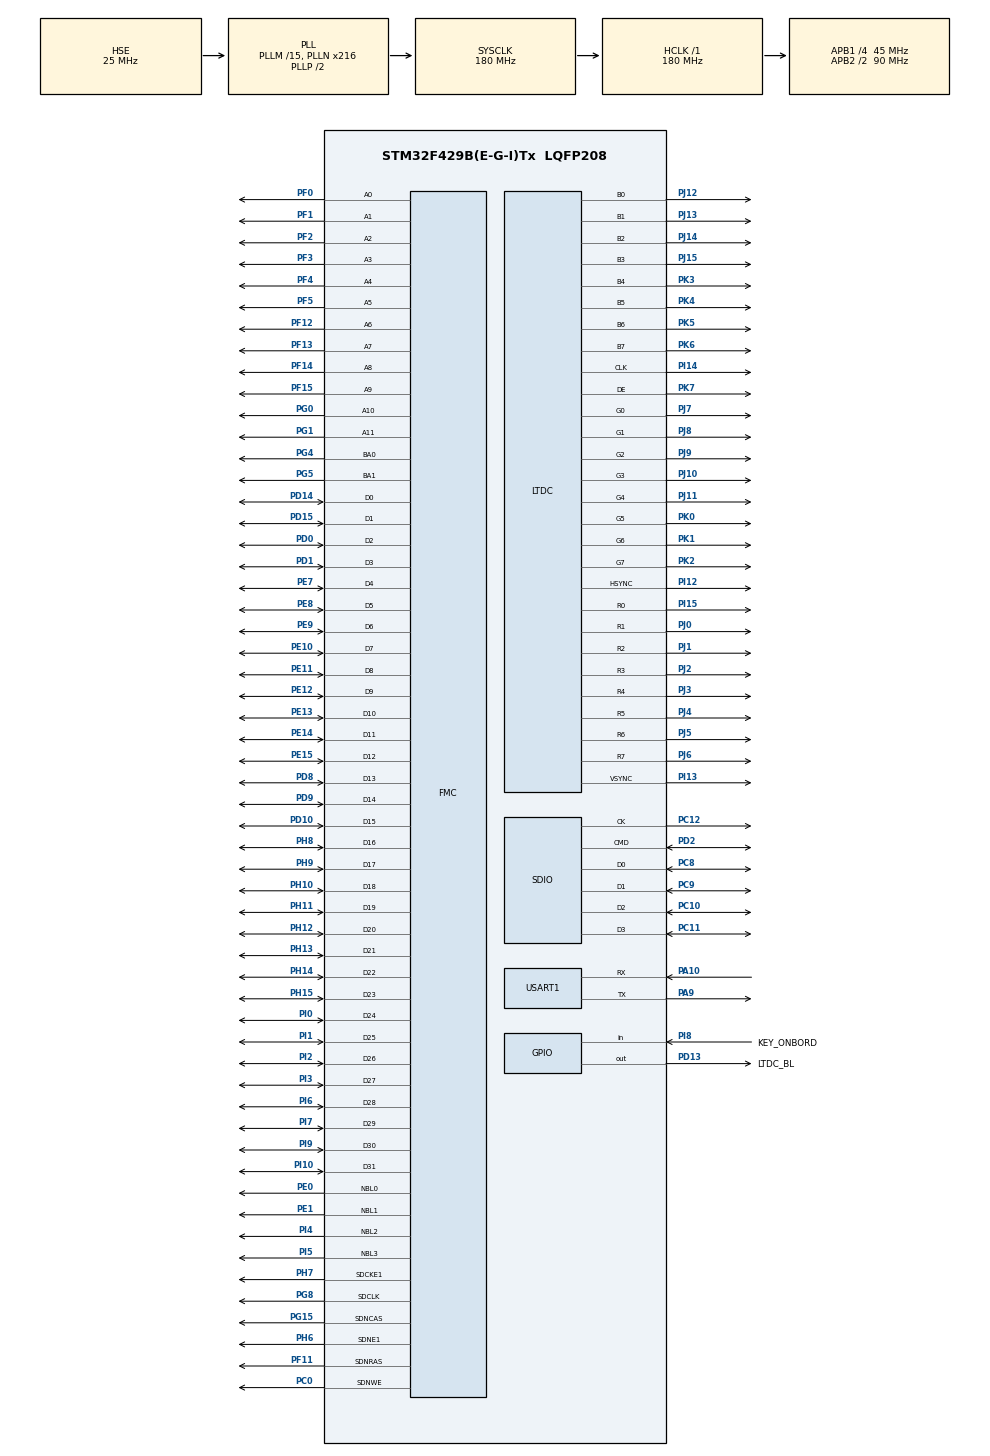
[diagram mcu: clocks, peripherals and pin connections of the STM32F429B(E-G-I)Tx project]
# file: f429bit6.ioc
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DMA2D.AlphaModeForeground=DMA2D_NO_MODIF_ALPHA
DMA2D.ColorMode=DMA2D_OUTPUT_ARGB8888
FMC.CASLatency2=FMC_SDRAM_CAS_LATENCY_3
FMC.ExitSelfRefreshDelay2=7
FMC.LoadToActiveDelay2=2
FMC.RCDDelay2=2
FMC.RPDelay2=2
FMC.ReadBurst2=FMC_SDRAM_RBURST_ENABLE
FMC.ReadPipeDelay2=FMC_SDRAM_RPIPE_DELAY_1
FMC.RowCycleDelay2=7
FMC.SDClockPeriod2=FMC_SDRAM_CLOCK_PERIOD_2
FMC.SelfRefreshTime2=4
FMC.WriteRecoveryTime2=3
LIBJPEG.HAVE_BOOLEAN=Undefined
LIBJPEG.LIBJPEG_FS_type=Stdio
LTDC.ActiveW=800
LTDC.Alpha0_L0=255
LTDC.Alpha0_L1=255
LTDC.HBP=46
LTDC.HFP=210
LTDC.HSync=1
LTDC.VBP=23
LTDC.VFP=22
LTDC.VSync=1
LTDC.WindowX1_L0=800
LTDC.WindowX1_L1=800
LTDC.WindowY1_L0=480
LTDC.WindowY1_L1=480
Mcu.Family=STM32F4
Mcu.Name=STM32F429B(E-G-I)Tx
Mcu.Package=LQFP208
NVIC.DMA2D_IRQn=true\:0\:0\:false\:false\:true\:true\:true\:true
NVIC.FMC_IRQn=true\:0\:0\:false\:false\:true\:true\:true\:true
NVIC.LTDC_ER_IRQn=true\:0\:0\:false\:false\:true\:true\:true\:true
NVIC.LTDC_IRQn=true\:0\:0\:false\:false\:true\:true\:true\:true
NVIC.PriorityGroup=NVIC_PRIORITYGROUP_4
NVIC.RCC_IRQn=true\:0\:0\:false\:false\:true\:true\:false\:true
NVIC.SDIO_IRQn=true\:1\:0\:true\:false\:true\:true\:true\:true
NVIC.TIM1_UP_TIM10_IRQn=true\:0\:0\:false\:false\:true\:true\:true\:true
NVIC.USART1_IRQn=true\:0\:0\:false\:false\:true\:true\:true\:true
PA10.Mode=Asynchronous
PA10.Signal=USART1_RX
PA13.Mode=Serial_Wire
PA13.Signal=SYS_JTMS-SWDIO
PA14.Mode=Serial_Wire
PA14.Signal=SYS_JTCK-SWCLK
PA9.Mode=Asynchronous
PA9.Signal=USART1_TX
PC0.Signal=FMC_SDNWE
PC10.GPIO_PuPd=GPIO_PULLUP
PC10.Mode=SD_4_bits_Wide_bus
PC10.Signal=SDIO_D2
PC11.GPIO_PuPd=GPIO_PULLUP
PC11.Mode=SD_4_bits_Wide_bus
PC11.Signal=SDIO_D3
PC12.GPIO_PuPd=GPIO_PULLDOWN
PC12.Mode=SD_4_bits_Wide_bus
PC12.Signal=SDIO_CK
PC14/OSC32_IN.Mode=LSE-External-Oscillator
PC14/OSC32_IN.Signal=RCC_OSC32_IN
PC15/OSC32_OUT.Mode=LSE-External-Oscillator
PC15/OSC32_OUT.Signal=RCC_OSC32_OUT
PC8.GPIO_PuPd=GPIO_PULLUP
PC8.Mode=SD_4_bits_Wide_bus
PC8.Signal=SDIO_D0
PC9.GPIO_PuPd=GPIO_PULLUP
PC9.Mode=SD_4_bits_Wide_bus
PC9.Signal=SDIO_D1
PD0.Signal=FMC_D2_DA2
PD1.Signal=FMC_D3_DA3
PD10.Signal=FMC_D15_DA15
PD13.GPIO_Label=LTDC_BL
PD13.Signal=GPIO_Output
PD14.Signal=FMC_D0_DA0
PD15.Signal=FMC_D1_DA1
PD2.GPIO_PuPd=GPIO_PULLUP
PD2.Mode=SD_4_bits_Wide_bus
PD2.Signal=SDIO_CMD
PD8.Signal=FMC_D13_DA13
PD9.Signal=FMC_D14_DA14
PE0.Signal=FMC_NBL0
PE1.Signal=FMC_NBL1
PE10.Signal=FMC_D7_DA7
PE11.Signal=FMC_D8_DA8
PE12.Signal=FMC_D9_DA9
PE13.Signal=FMC_D10_DA10
PE14.Signal=FMC_D11_DA11
PE15.Signal=FMC_D12_DA12
PE7.Signal=FMC_D4_DA4
PE8.Signal=FMC_D5_DA5
PE9.Signal=FMC_D6_DA6
PF0.Signal=FMC_A0
PF1.Signal=FMC_A1
PF11.Signal=FMC_SDNRAS
PF12.Signal=FMC_A6
PF13.Signal=FMC_A7
PF14.Signal=FMC_A8
PF15.Signal=FMC_A9
PF2.Signal=FMC_A2
PF3.Signal=FMC_A3
PF4.Signal=FMC_A4
PF5.Signal=FMC_A5
PG0.Signal=FMC_A10
PG1.Signal=FMC_A11
PG15.Signal=FMC_SDNCAS
PG4.Signal=FMC_A14_BA0
PG5.Signal=FMC_A15_BA1
PG8.Signal=FMC_SDCLK
PH0/OSC_IN.Mode=HSE-External-Oscillator
PH0/OSC_IN.Signal=RCC_OSC_IN
PH1/OSC_OUT.Mode=HSE-External-Oscillator
PH1/OSC_OUT.Signal=RCC_OSC_OUT
PH10.Signal=FMC_D18
PH11.Signal=FMC_D19
PH12.Signal=FMC_D20
PH13.Signal=FMC_D21
PH14.Signal=FMC_D22
PH15.Signal=FMC_D23
PH6.Mode=SdramChipSelect2_2
PH6.Signal=FMC_SDNE1
PH7.Mode=SdramChipSelect2_2
PH7.Signal=FMC_SDCKE1
PH8.Signal=FMC_D16
PH9.Signal=FMC_D17
PI0.Signal=FMC_D24
PI1.Signal=FMC_D25
PI10.Signal=FMC_D31
PI12.Mode=RGB888
PI12.Signal=LTDC_HSYNC
PI13.Mode=RGB888
PI13.Signal=LTDC_VSYNC
PI14.Mode=RGB888
PI14.Signal=LTDC_CLK
PI15.Mode=RGB888
PI15.Signal=LTDC_R0
PI2.Signal=FMC_D26
PI3.Signal=FMC_D27
PI4.Signal=FMC_NBL2
PI5.Signal=FMC_NBL3
PI6.Signal=FMC_D28
PI7.Signal=FMC_D29
PI8.GPIO_Label=KEY_ONBORD
PI8.Signal=GPIO_Input
PI9.Signal=FMC_D30
PJ0.Mode=RGB888
PJ0.Signal=LTDC_R1
PJ1.Mode=RGB888
PJ1.Signal=LTDC_R2
PJ10.Mode=RGB888
PJ10.Signal=LTDC_G3
PJ11.Mode=RGB888
PJ11.Signal=LTDC_G4
PJ12.Mode=RGB888
PJ12.Signal=LTDC_B0
PJ13.Mode=RGB888
PJ13.Signal=LTDC_B1
PJ14.Mode=RGB888
PJ14.Signal=LTDC_B2
PJ15.Mode=RGB888
PJ15.Signal=LTDC_B3
PJ2.Mode=RGB888
PJ2.Signal=LTDC_R3
PJ3.Mode=RGB888
PJ3.Signal=LTDC_R4
PJ4.Mode=RGB888
PJ4.Signal=LTDC_R5
PJ5.Mode=RGB888
PJ5.Signal=LTDC_R6
PJ6.Mode=RGB888
PJ6.Signal=LTDC_R7
PJ7.Mode=RGB888
PJ7.Signal=LTDC_G0
PJ8.Mode=RGB888
PJ8.Signal=LTDC_G1
PJ9.Mode=RGB888
PJ9.Signal=LTDC_G2
PK0.Mode=RGB888
PK0.Signal=LTDC_G5
PK1.Mode=RGB888
PK1.Signal=LTDC_G6
PK2.Mode=RGB888
PK2.Signal=LTDC_G7
PK3.Mode=RGB888
PK3.Signal=LTDC_B4
PK4.Mode=RGB888
PK4.Signal=LTDC_B5
PK5.Mode=RGB888
PK5.Signal=LTDC_B6
PK6.Mode=RGB888
PK6.Signal=LTDC_B7
PK7.Mode=RGB888
PK7.Signal=LTDC_DE
ProjectManager.HeapSize=0x200
ProjectManager.StackSize=0x400
ProjectManager.TargetToolchain=Makefile
RCC.48MHZClocksFreq_Value=45000000
RCC.AHBFreq_Value=180000000
RCC.APB1CLKDivider=RCC_HCLK_DIV4
RCC.APB1Freq_Value=45000000
RCC.APB1TimFreq_Value=90000000
RCC.APB2CLKDivider=RCC_HCLK_DIV2
RCC.APB2Freq_Value=90000000
RCC.APB2TimFreq_Value=180000000
RCC.CortexFreq_Value=180000000
RCC.HCLKFreq_Value=180000000
RCC.HSE_VALUE=25000000
RCC.HSI_VALUE=16000000
RCC.PLLM=15
RCC.PLLN=216
RCC.PLLQ=8
RCC.PLLSAIN=60
RCC.PLLSourceVirtual=RCC_PLLSOURCE_HSE
RCC.RCC_RTC_Clock_Source=RCC_RTCCLKSOURCE_LSE
RCC.RCC_RTC_Clock_SourceVirtual=RCC_RTCCLKSOURCE_LSE
RCC.RCC_RTC_Clock_Source_FROM_HSE=RCC_RTCCLKSOURCE_HSE_DIV25
RCC.SYSCLKFreq_VALUE=180000000
RCC.SYSCLKSource=RCC_SYSCLKSOURCE_PLLCLK
RCC.VCOOutputFreq_Value=360000000
SDIO.ClockDiv=8
SDIO.ClockEdge=SDIO_CLOCK_EDGE_RISING
SDIO.HardwareFlowControl=SDIO_HARDWARE_FLOW_CONTROL_DISABLE
SH.FMC_A0.0=FMC_A0,12b-sda2
SH.FMC_A1.0=FMC_A1,12b-sda2
SH.FMC_A10.0=FMC_A10,12b-sda2
SH.FMC_A11.0=FMC_A11,12b-sda2
SH.FMC_A14_BA0.0=FMC_BA0,FourSdramBanks2
SH.FMC_A15_BA1.0=FMC_BA1,FourSdramBanks2
SH.FMC_A2.0=FMC_A2,12b-sda2
SH.FMC_A3.0=FMC_A3,12b-sda2
SH.FMC_A4.0=FMC_A4,12b-sda2
SH.FMC_A5.0=FMC_A5,12b-sda2
SH.FMC_A6.0=FMC_A6,12b-sda2
SH.FMC_A7.0=FMC_A7,12b-sda2
SH.FMC_A8.0=FMC_A8,12b-sda2
SH.FMC_A9.0=FMC_A9,12b-sda2
SH.FMC_D0_DA0.0=FMC_D0,sd-32b-d2
SH.FMC_D10_DA10.0=FMC_D10,sd-32b-d2
SH.FMC_D11_DA11.0=FMC_D11,sd-32b-d2
SH.FMC_D12_DA12.0=FMC_D12,sd-32b-d2
SH.FMC_D13_DA13.0=FMC_D13,sd-32b-d2
SH.FMC_D14_DA14.0=FMC_D14,sd-32b-d2
SH.FMC_D15_DA15.0=FMC_D15,sd-32b-d2
SH.FMC_D16.0=FMC_D16,sd-32b-d2
SH.FMC_D17.0=FMC_D17,sd-32b-d2
SH.FMC_D18.0=FMC_D18,sd-32b-d2
SH.FMC_D19.0=FMC_D19,sd-32b-d2
SH.FMC_D1_DA1.0=FMC_D1,sd-32b-d2
SH.FMC_D20.0=FMC_D20,sd-32b-d2
SH.FMC_D21.0=FMC_D21,sd-32b-d2
SH.FMC_D22.0=FMC_D22,sd-32b-d2
SH.FMC_D23.0=FMC_D23,sd-32b-d2
SH.FMC_D24.0=FMC_D24,sd-32b-d2
SH.FMC_D25.0=FMC_D25,sd-32b-d2
SH.FMC_D26.0=FMC_D26,sd-32b-d2
SH.FMC_D27.0=FMC_D27,sd-32b-d2
SH.FMC_D28.0=FMC_D28,sd-32b-d2
SH.FMC_D29.0=FMC_D29,sd-32b-d2
SH.FMC_D2_DA2.0=FMC_D2,sd-32b-d2
SH.FMC_D30.0=FMC_D30,sd-32b-d2
SH.FMC_D31.0=FMC_D31,sd-32b-d2
SH.FMC_D3_DA3.0=FMC_D3,sd-32b-d2
SH.FMC_D4_DA4.0=FMC_D4,sd-32b-d2
SH.FMC_D5_DA5.0=FMC_D5,sd-32b-d2
SH.FMC_D6_DA6.0=FMC_D6,sd-32b-d2
SH.FMC_D7_DA7.0=FMC_D7,sd-32b-d2
SH.FMC_D8_DA8.0=FMC_D8,sd-32b-d2
SH.FMC_D9_DA9.0=FMC_D9,sd-32b-d2
SH.FMC_NBL0.0=FMC_NBL0,Sd4ByteEnable2
SH.FMC_NBL1.0=FMC_NBL1,Sd4ByteEnable2
SH.FMC_NBL2.0=FMC_NBL2,Sd4ByteEnable2
SH.FMC_NBL3.0=FMC_NBL3,Sd4ByteEnable2
SH.FMC_SDCLK.0=FMC_SDCLK,12b-sda2
SH.FMC_SDNCAS.0=FMC_SDNCAS,12b-sda2
SH.FMC_SDNRAS.0=FMC_SDNRAS,12b-sda2
SH.FMC_SDNWE.0=FMC_SDNWE,12b-sda2
TIM1.AutoReloadPreload=TIM_AUTORELOAD_PRELOAD_ENABLE
TIM1.ClockDivision=TIM_CLOCKDIVISION_DIV1
TIM1.Period=50000
TIM1.Prescaler=180
USART1.VirtualMode=VM_ASYNC
VP_DMA2D_VS_DMA2D.Mode=DMA2D_Activate
VP_FATFS_VS_SDIO.Mode=SDIO
VP_LIBJPEG_VS_JPEGLIB.Mode=Enabled
VP_RTC_VS_RTC_Activate.Mode=RTC_Enabled
VP_TIM1_VS_ClockSourceINT.Mode=Internal
board=custom

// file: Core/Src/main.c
/* USER CODE BEGIN Header */
/**
 ******************************************************************************
 * @file           : main.c
 * @brief          : Main program body
 ******************************************************************************
 * @attention
 *
 * Copyright (c) 2023 STMicroelectronics.
 * All rights reserved.
 *
 * This software is licensed under terms that can be found in the LICENSE file
 * in the root directory of this software component.
 * If no LICENSE file comes with this software, it is provided AS-IS.
 *
 ******************************************************************************
 */
/* USER CODE END Header */
#include "main.h"
#include "fatfs.h"

/* USER CODE BEGIN Includes */
#include "lcd.h"
#include "sdram.h"

/* USER CODE END Includes */

DMA2D_HandleTypeDef hdma2d;

LTDC_HandleTypeDef hltdc;

RTC_HandleTypeDef hrtc;

SD_HandleTypeDef hsd;

TIM_HandleTypeDef htim1;

UART_HandleTypeDef huart1;

SDRAM_HandleTypeDef hsdram2;

/* USER CODE BEGIN PV */

// cmd
FMC_SDRAM_CommandTypeDef command;

/* USER CODE END PV */

void SystemClock_Config(void);
static void MX_GPIO_Init(void);
static void MX_FMC_Init(void);
static void MX_USART1_UART_Init(void);
static void MX_DMA2D_Init(void);
static void MX_LTDC_Init(void);
static void MX_RTC_Init(void);
static void MX_TIM1_Init(void);
static void MX_SDIO_SD_Init(void);

int main(void)
{

  /* MCU Configuration--------------------------------------------------------*/

  /* Reset of all peripherals, Initializes the Flash interface and the Systick. */
  HAL_Init();

  /* Configure the system clock */
  SystemClock_Config();

  /* Initialize all configured peripherals */
  MX_GPIO_Init();
  MX_FMC_Init();
  MX_USART1_UART_Init();
  MX_DMA2D_Init();
  MX_LTDC_Init();
  MX_RTC_Init();
  MX_TIM1_Init();
  MX_SDIO_SD_Init();
  MX_FATFS_Init();

  /* Infinite loop */
  /* USER CODE BEGIN WHILE */

    GPIO_InitTypeDef GPIO_InitStruct = {0};

    HAL_GPIO_WritePin(GPIOD, GPIO_PIN_12,
                      GPIO_PIN_RESET);  // LED1引脚输出低，即点亮LED1
    HAL_GPIO_WritePin(GPIOG, GPIO_PIN_7,
                      GPIO_PIN_RESET);  // LED2引脚输出低，即点亮LED2

    GPIO_InitStruct.Pin = GPIO_PIN_12;           // LED1引脚
    GPIO_InitStruct.Mode = GPIO_MODE_OUTPUT_PP;  // 推挽输出模式
    GPIO_InitStruct.Pull = GPIO_NOPULL;          // 不上下拉
    GPIO_InitStruct.Speed = GPIO_SPEED_FREQ_LOW;
    HAL_GPIO_Init(GPIOD, &GPIO_InitStruct);

    GPIO_InitStruct.Pin = GPIO_PIN_7;  // LED2引脚
    HAL_GPIO_Init(GPIOG, &GPIO_InitStruct);

    while (1) {
    /* USER CODE END WHILE */

    /* USER CODE BEGIN 3 */
        // JMP to user application main
        extern void maMain(void);
        maMain();
    }
  /* USER CODE END 3 */
}

void SystemClock_Config(void)
{
  RCC_OscInitTypeDef RCC_OscInitStruct = {0};
  RCC_ClkInitTypeDef RCC_ClkInitStruct = {0};

  /** Configure the main internal regulator output voltage
  */
  __HAL_RCC_PWR_CLK_ENABLE();
  __HAL_PWR_VOLTAGESCALING_CONFIG(PWR_REGULATOR_VOLTAGE_SCALE1);

  /** Initializes the RCC Oscillators according to the specified parameters
  * in the RCC_OscInitTypeDef structure.
  */
  RCC_OscInitStruct.OscillatorType = RCC_OSCILLATORTYPE_HSE|RCC_OSCILLATORTYPE_LSE;
  RCC_OscInitStruct.HSEState = RCC_HSE_ON;
  RCC_OscInitStruct.LSEState = RCC_LSE_ON;
  RCC_OscInitStruct.PLL.PLLState = RCC_PLL_ON;
  RCC_OscInitStruct.PLL.PLLSource = RCC_PLLSOURCE_HSE;
  RCC_OscInitStruct.PLL.PLLM = 15;
  RCC_OscInitStruct.PLL.PLLN = 216;
  RCC_OscInitStruct.PLL.PLLP = RCC_PLLP_DIV2;
  RCC_OscInitStruct.PLL.PLLQ = 8;
  if (HAL_RCC_OscConfig(&RCC_OscInitStruct) != HAL_OK)
  {
    Error_Handler();
  }

  /** Activate the Over-Drive mode
  */
  if (HAL_PWREx_EnableOverDrive() != HAL_OK)
  {
    Error_Handler();
  }

  /** Initializes the CPU, AHB and APB buses clocks
  */
  RCC_ClkInitStruct.ClockType = RCC_CLOCKTYPE_HCLK|RCC_CLOCKTYPE_SYSCLK
                              |RCC_CLOCKTYPE_PCLK1|RCC_CLOCKTYPE_PCLK2;
  RCC_ClkInitStruct.SYSCLKSource = RCC_SYSCLKSOURCE_PLLCLK;
  RCC_ClkInitStruct.AHBCLKDivider = RCC_SYSCLK_DIV1;
  RCC_ClkInitStruct.APB1CLKDivider = RCC_HCLK_DIV4;
  RCC_ClkInitStruct.APB2CLKDivider = RCC_HCLK_DIV2;

  if (HAL_RCC_ClockConfig(&RCC_ClkInitStruct, FLASH_LATENCY_5) != HAL_OK)
  {
    Error_Handler();
  }
}

static void MX_DMA2D_Init(void)
{

  hdma2d.Instance = DMA2D;
  hdma2d.Init.Mode = DMA2D_M2M;
  hdma2d.Init.ColorMode = DMA2D_OUTPUT_ARGB8888;
  hdma2d.Init.OutputOffset = 0;
  hdma2d.LayerCfg[1].InputOffset = 0;
  hdma2d.LayerCfg[1].InputColorMode = DMA2D_INPUT_ARGB8888;
  hdma2d.LayerCfg[1].AlphaMode = DMA2D_NO_MODIF_ALPHA;
  hdma2d.LayerCfg[1].InputAlpha = 0;
  if (HAL_DMA2D_Init(&hdma2d) != HAL_OK)
  {
    Error_Handler();
  }
  if (HAL_DMA2D_ConfigLayer(&hdma2d, 1) != HAL_OK)
  {
    Error_Handler();
  }

}

static void MX_LTDC_Init(void)
{

  LTDC_LayerCfgTypeDef pLayerCfg = {0};
  LTDC_LayerCfgTypeDef pLayerCfg1 = {0};

  hltdc.Instance = LTDC;
  hltdc.Init.HSPolarity = LTDC_HSPOLARITY_AL;
  hltdc.Init.VSPolarity = LTDC_VSPOLARITY_AL;
  hltdc.Init.DEPolarity = LTDC_DEPOLARITY_AL;
  hltdc.Init.PCPolarity = LTDC_PCPOLARITY_IPC;
  hltdc.Init.HorizontalSync = 0;
  hltdc.Init.VerticalSync = 0;
  hltdc.Init.AccumulatedHBP = 46;
  hltdc.Init.AccumulatedVBP = 23;
  hltdc.Init.AccumulatedActiveW = 846;
  hltdc.Init.AccumulatedActiveH = 503;
  hltdc.Init.TotalWidth = 1056;
  hltdc.Init.TotalHeigh = 525;
  hltdc.Init.Backcolor.Blue = 0;
  hltdc.Init.Backcolor.Green = 0;
  hltdc.Init.Backcolor.Red = 0;
  if (HAL_LTDC_Init(&hltdc) != HAL_OK)
  {
    Error_Handler();
  }
  pLayerCfg.WindowX0 = 0;
  pLayerCfg.WindowX1 = 800;
  pLayerCfg.WindowY0 = 0;
  pLayerCfg.WindowY1 = 480;
  pLayerCfg.PixelFormat = LTDC_PIXEL_FORMAT_ARGB8888;
  pLayerCfg.Alpha = 0;
  pLayerCfg.Alpha0 = 255;
  pLayerCfg.BlendingFactor1 = LTDC_BLENDING_FACTOR1_CA;
  pLayerCfg.BlendingFactor2 = LTDC_BLENDING_FACTOR2_CA;
  pLayerCfg.FBStartAdress = 0;
  pLayerCfg.ImageWidth = 0;
  pLayerCfg.ImageHeight = 0;
  pLayerCfg.Backcolor.Blue = 0;
  pLayerCfg.Backcolor.Green = 0;
  pLayerCfg.Backcolor.Red = 0;
  if (HAL_LTDC_ConfigLayer(&hltdc, &pLayerCfg, 0) != HAL_OK)
  {
    Error_Handler();
  }
  pLayerCfg1.WindowX0 = 0;
  pLayerCfg1.WindowX1 = 800;
  pLayerCfg1.WindowY0 = 0;
  pLayerCfg1.WindowY1 = 480;
  pLayerCfg1.PixelFormat = LTDC_PIXEL_FORMAT_ARGB8888;
  pLayerCfg1.Alpha = 0;
  pLayerCfg1.Alpha0 = 255;
  pLayerCfg1.BlendingFactor1 = LTDC_BLENDING_FACTOR1_CA;
  pLayerCfg1.BlendingFactor2 = LTDC_BLENDING_FACTOR2_CA;
  pLayerCfg1.FBStartAdress = 0;
  pLayerCfg1.ImageWidth = 0;
  pLayerCfg1.ImageHeight = 0;
  pLayerCfg1.Backcolor.Blue = 0;
  pLayerCfg1.Backcolor.Green = 0;
  pLayerCfg1.Backcolor.Red = 0;
  if (HAL_LTDC_ConfigLayer(&hltdc, &pLayerCfg1, 1) != HAL_OK)
  {
    Error_Handler();
  }
  /* USER CODE BEGIN LTDC_Init 2 */

    hltdc.Instance = LTDC;
    hltdc.Init.HSPolarity = LTDC_HSPOLARITY_AL;
    hltdc.Init.VSPolarity = LTDC_VSPOLARITY_AL;
    hltdc.Init.DEPolarity = LTDC_DEPOLARITY_AL;
    hltdc.Init.PCPolarity = LTDC_PCPOLARITY_IPC;

    hltdc.Init.HorizontalSync = LCD_HSW - 1;
    hltdc.Init.VerticalSync = LCD_VSW - 1;
    hltdc.Init.AccumulatedHBP = LCD_HBP + LCD_HSW - 1;
    hltdc.Init.AccumulatedVBP = LCD_VBP + LCD_VSW - 1;
    hltdc.Init.AccumulatedActiveW = LCD_Width + LCD_HSW + LCD_HBP - 1;
    hltdc.Init.AccumulatedActiveH = LCD_Height + LCD_VSW + LCD_VBP - 1;
    hltdc.Init.TotalWidth = LCD_Width + LCD_HSW + LCD_HBP + LCD_HFP - 1;
    hltdc.Init.TotalHeigh = LCD_Height + LCD_VSW + LCD_VBP + LCD_VFP - 1;
    hltdc.Init.Backcolor.Blue = 0;
    hltdc.Init.Backcolor.Green = 0;
    hltdc.Init.Backcolor.Red = 0;

    HAL_LTDC_Init(&hltdc);  // 初始化LTDC

    pLayerCfg.WindowX0 = 0;               // 水平起点
    pLayerCfg.WindowX1 = LCD_Width;       // 水平终点
    pLayerCfg.WindowY0 = 0;               // 垂直起点
    pLayerCfg.WindowY1 = LCD_Height;      // 垂直终点
    pLayerCfg.PixelFormat = ColorMode_0;  // 颜色格式
    pLayerCfg.ImageWidth = LCD_Width;     // 显示区域宽度
    pLayerCfg.ImageHeight = LCD_Height;   // 显示区域高度

    pLayerCfg.Alpha = 255;

    pLayerCfg.BlendingFactor1 = LTDC_BLENDING_FACTOR1_PAxCA;
    pLayerCfg.BlendingFactor2 = LTDC_BLENDING_FACTOR2_PAxCA;

    // 显存地址
    pLayerCfg.FBStartAdress = (uint32_t)(&lcd_vram[0][0]);

    pLayerCfg.Alpha0 = 0;
    pLayerCfg.Backcolor.Blue = 0;
    pLayerCfg.Backcolor.Green = 0;
    pLayerCfg.Backcolor.Red = 0;

    HAL_LTDC_ConfigLayer(&hltdc, &pLayerCfg, 0);  // 配置�??????????0，背景层

#if ((ColorMode_0 == LTDC_PIXEL_FORMAT_RGB888) || \
     (ColorMode_0 == LTDC_PIXEL_FORMAT_ARGB8888))  // 判断是否使用24位或32位色

    // 使能颜色抖动�??????????24位以上的颜色必须打开，否则无法达到相应的效果
    HAL_LTDC_EnableDither(&hltdc);

    // 当颜色格式为24位色时，重新设置帧缓冲区的寄存器，按�??????????32位格式来设置，即每个像素�??????????4字节
    // 如果使用HAL库默认的设置，在刷屏或�?�显示字符的时�?�，容易造成屏幕花屏
    // 这里设置的只是帧缓冲区的格式，和SDRAM显存无关
    LTDC_Layer1->CFBLR = (LCD_Width * 4 << 16) | (LCD_Width * 4 + 3);
    HAL_LTDC_Reload(&hltdc, LTDC_RELOAD_VERTICAL_BLANKING);  // 重新载入参数
#endif

    // layer1 显示配置

#if (LCD_NUM_LAYERS == 2)  // 当定义了双层

    pLayerCfg1.WindowX0 = 0;               // 水平起点
    pLayerCfg1.WindowX1 = LCD_Width;       // 水平终点
    pLayerCfg1.WindowY0 = 0;               // 垂直起点
    pLayerCfg1.WindowY1 = LCD_Height;      // 垂直终点
    pLayerCfg1.PixelFormat = ColorMode_1;  // 颜色格式
    pLayerCfg1.ImageWidth = LCD_Width;     // 显示区域宽度
    pLayerCfg1.ImageHeight = LCD_Height;   // 显示区域高度

    pLayerCfg1.Alpha = 255;

    pLayerCfg1.BlendingFactor1 = LTDC_BLENDING_FACTOR1_PAxCA;  // 混合系数
    pLayerCfg1.BlendingFactor2 = LTDC_BLENDING_FACTOR2_PAxCA;  // 混合系数

    // layer1

    pLayerCfg1.FBStartAdress = (uint32_t)(&lcd_vram[1][0]);  // 显存地址

    pLayerCfg1.Alpha0 = 0;
    pLayerCfg1.Backcolor.Blue = 0;
    pLayerCfg1.Backcolor.Green = 0;
    pLayerCfg1.Backcolor.Red = 0;

    HAL_LTDC_ConfigLayer(&hltdc, &pLayerCfg1, 1);

#if ((ColorMode_1 == LTDC_PIXEL_FORMAT_RGB888) || \
     (ColorMode_1 == LTDC_PIXEL_FORMAT_ARGB8888))

    HAL_LTDC_EnableDither(&hltdc);

    LTDC_Layer2->CFBLR = (LCD_Width * 4 << 16) | (LCD_Width * 4 + 3);
    HAL_LTDC_Reload(&hltdc, LTDC_RELOAD_VERTICAL_BLANKING);  // 重新载入参数
#endif

#endif

    LCD_Init();
  /* USER CODE END LTDC_Init 2 */

}

static void MX_RTC_Init(void)
{

  /** Initialize RTC Only
  */
  hrtc.Instance = RTC;
  hrtc.Init.HourFormat = RTC_HOURFORMAT_24;
  hrtc.Init.AsynchPrediv = 127;
  hrtc.Init.SynchPrediv = 255;
  hrtc.Init.OutPut = RTC_OUTPUT_DISABLE;
  hrtc.Init.OutPutPolarity = RTC_OUTPUT_POLARITY_HIGH;
  hrtc.Init.OutPutType = RTC_OUTPUT_TYPE_OPENDRAIN;
  if (HAL_RTC_Init(&hrtc) != HAL_OK)
  {
    Error_Handler();
  }

}

static void MX_SDIO_SD_Init(void)
{

  hsd.Instance = SDIO;
  hsd.Init.ClockEdge = SDIO_CLOCK_EDGE_RISING;
  hsd.Init.ClockBypass = SDIO_CLOCK_BYPASS_DISABLE;
  hsd.Init.ClockPowerSave = SDIO_CLOCK_POWER_SAVE_DISABLE;
  hsd.Init.BusWide = SDIO_BUS_WIDE_1B;
  hsd.Init.HardwareFlowControl = SDIO_HARDWARE_FLOW_CONTROL_DISABLE;
  hsd.Init.ClockDiv = 8;

}

static void MX_TIM1_Init(void)
{

  TIM_ClockConfigTypeDef sClockSourceConfig = {0};
  TIM_MasterConfigTypeDef sMasterConfig = {0};

  htim1.Instance = TIM1;
  htim1.Init.Prescaler = 180;
  htim1.Init.CounterMode = TIM_COUNTERMODE_UP;
  htim1.Init.Period = 50000;
  htim1.Init.ClockDivision = TIM_CLOCKDIVISION_DIV1;
  htim1.Init.RepetitionCounter = 0;
  htim1.Init.AutoReloadPreload = TIM_AUTORELOAD_PRELOAD_ENABLE;
  if (HAL_TIM_Base_Init(&htim1) != HAL_OK)
  {
    Error_Handler();
  }
  sClockSourceConfig.ClockSource = TIM_CLOCKSOURCE_INTERNAL;
  if (HAL_TIM_ConfigClockSource(&htim1, &sClockSourceConfig) != HAL_OK)
  {
    Error_Handler();
  }
  sMasterConfig.MasterOutputTrigger = TIM_TRGO_RESET;
  sMasterConfig.MasterSlaveMode = TIM_MASTERSLAVEMODE_DISABLE;
  if (HAL_TIMEx_MasterConfigSynchronization(&htim1, &sMasterConfig) != HAL_OK)
  {
    Error_Handler();
  }
  /* USER CODE BEGIN TIM1_Init 2 */
    HAL_TIM_Base_Start_IT(&htim1);

  /* USER CODE END TIM1_Init 2 */

}

static void MX_USART1_UART_Init(void)
{

  huart1.Instance = USART1;
  huart1.Init.BaudRate = 115200;
  huart1.Init.WordLength = UART_WORDLENGTH_8B;
  huart1.Init.StopBits = UART_STOPBITS_1;
  huart1.Init.Parity = UART_PARITY_NONE;
  huart1.Init.Mode = UART_MODE_TX_RX;
  huart1.Init.HwFlowCtl = UART_HWCONTROL_NONE;
  huart1.Init.OverSampling = UART_OVERSAMPLING_16;
  if (HAL_UART_Init(&huart1) != HAL_OK)
  {
    Error_Handler();
  }

}

/* FMC initialization function */
static void MX_FMC_Init(void)
{

  FMC_SDRAM_TimingTypeDef SdramTiming = {0};

  /** Perform the SDRAM2 memory initialization sequence
  */
  hsdram2.Instance = FMC_SDRAM_DEVICE;
  /* hsdram2.Init */
  hsdram2.Init.SDBank = FMC_SDRAM_BANK2;
  hsdram2.Init.ColumnBitsNumber = FMC_SDRAM_COLUMN_BITS_NUM_8;
  hsdram2.Init.RowBitsNumber = FMC_SDRAM_ROW_BITS_NUM_12;
  hsdram2.Init.MemoryDataWidth = FMC_SDRAM_MEM_BUS_WIDTH_32;
  hsdram2.Init.InternalBankNumber = FMC_SDRAM_INTERN_BANKS_NUM_4;
  hsdram2.Init.CASLatency = FMC_SDRAM_CAS_LATENCY_3;
  hsdram2.Init.WriteProtection = FMC_SDRAM_WRITE_PROTECTION_DISABLE;
  hsdram2.Init.SDClockPeriod = FMC_SDRAM_CLOCK_PERIOD_2;
  hsdram2.Init.ReadBurst = FMC_SDRAM_RBURST_ENABLE;
  hsdram2.Init.ReadPipeDelay = FMC_SDRAM_RPIPE_DELAY_1;
  /* SdramTiming */
  SdramTiming.LoadToActiveDelay = 2;
  SdramTiming.ExitSelfRefreshDelay = 7;
  SdramTiming.SelfRefreshTime = 4;
  SdramTiming.RowCycleDelay = 7;
  SdramTiming.WriteRecoveryTime = 3;
  SdramTiming.RPDelay = 2;
  SdramTiming.RCDDelay = 2;

  if (HAL_SDRAM_Init(&hsdram2, &SdramTiming) != HAL_OK)
  {
    Error_Handler( );
  }

  /* USER CODE BEGIN FMC_Init 2 */
    m_hw_sdram_init(&hsdram2, &command);
  /* USER CODE END FMC_Init 2 */
}

static void MX_GPIO_Init(void)
{
  GPIO_InitTypeDef GPIO_InitStruct = {0};

  /* GPIO Ports Clock Enable */
  __HAL_RCC_GPIOI_CLK_ENABLE();
  __HAL_RCC_GPIOC_CLK_ENABLE();
  __HAL_RCC_GPIOF_CLK_ENABLE();
  __HAL_RCC_GPIOH_CLK_ENABLE();
  __HAL_RCC_GPIOJ_CLK_ENABLE();
  __HAL_RCC_GPIOG_CLK_ENABLE();
  __HAL_RCC_GPIOE_CLK_ENABLE();
  __HAL_RCC_GPIOD_CLK_ENABLE();
  __HAL_RCC_GPIOK_CLK_ENABLE();
  __HAL_RCC_GPIOA_CLK_ENABLE();

  /*Configure GPIO pin Output Level */
  HAL_GPIO_WritePin(LTDC_BL_GPIO_Port, LTDC_BL_Pin, GPIO_PIN_RESET);

  /*Configure GPIO pin : KEY_ONBORD_Pin */
  GPIO_InitStruct.Pin = KEY_ONBORD_Pin;
  GPIO_InitStruct.Mode = GPIO_MODE_INPUT;
  GPIO_InitStruct.Pull = GPIO_NOPULL;
  HAL_GPIO_Init(KEY_ONBORD_GPIO_Port, &GPIO_InitStruct);

  /*Configure GPIO pin : LTDC_BL_Pin */
  GPIO_InitStruct.Pin = LTDC_BL_Pin;
  GPIO_InitStruct.Mode = GPIO_MODE_OUTPUT_PP;
  GPIO_InitStruct.Pull = GPIO_NOPULL;
  GPIO_InitStruct.Speed = GPIO_SPEED_FREQ_LOW;
  HAL_GPIO_Init(LTDC_BL_GPIO_Port, &GPIO_InitStruct);

}

void Error_Handler(void)
{
  /* USER CODE BEGIN Error_Handler_Debug */
    /* User can add his own implementation to report the HAL error return state
     */
    __disable_irq();
    while (1) {
        extern void error_led_light(void);
        error_led_light();
    }
  /* USER CODE END Error_Handler_Debug */
}

#ifdef  USE_FULL_ASSERT
/**
  * @brief  Reports the name of the source file and the source line number
  *         where the assert_param error has occurred.
  * @param  file: pointer to the source file name
  * @param  line: assert_param error line source number
  * @retval None
  */
void assert_failed(uint8_t *file, uint32_t line)
{
  /* USER CODE BEGIN 6 */
    /* User can add his own implementation to report the file name and line
       number, ex: printf("Wrong parameters value: file %s on line %d\r\n",
       file, line) */
  /* USER CODE END 6 */
}
#endif /* USE_FULL_ASSERT */
